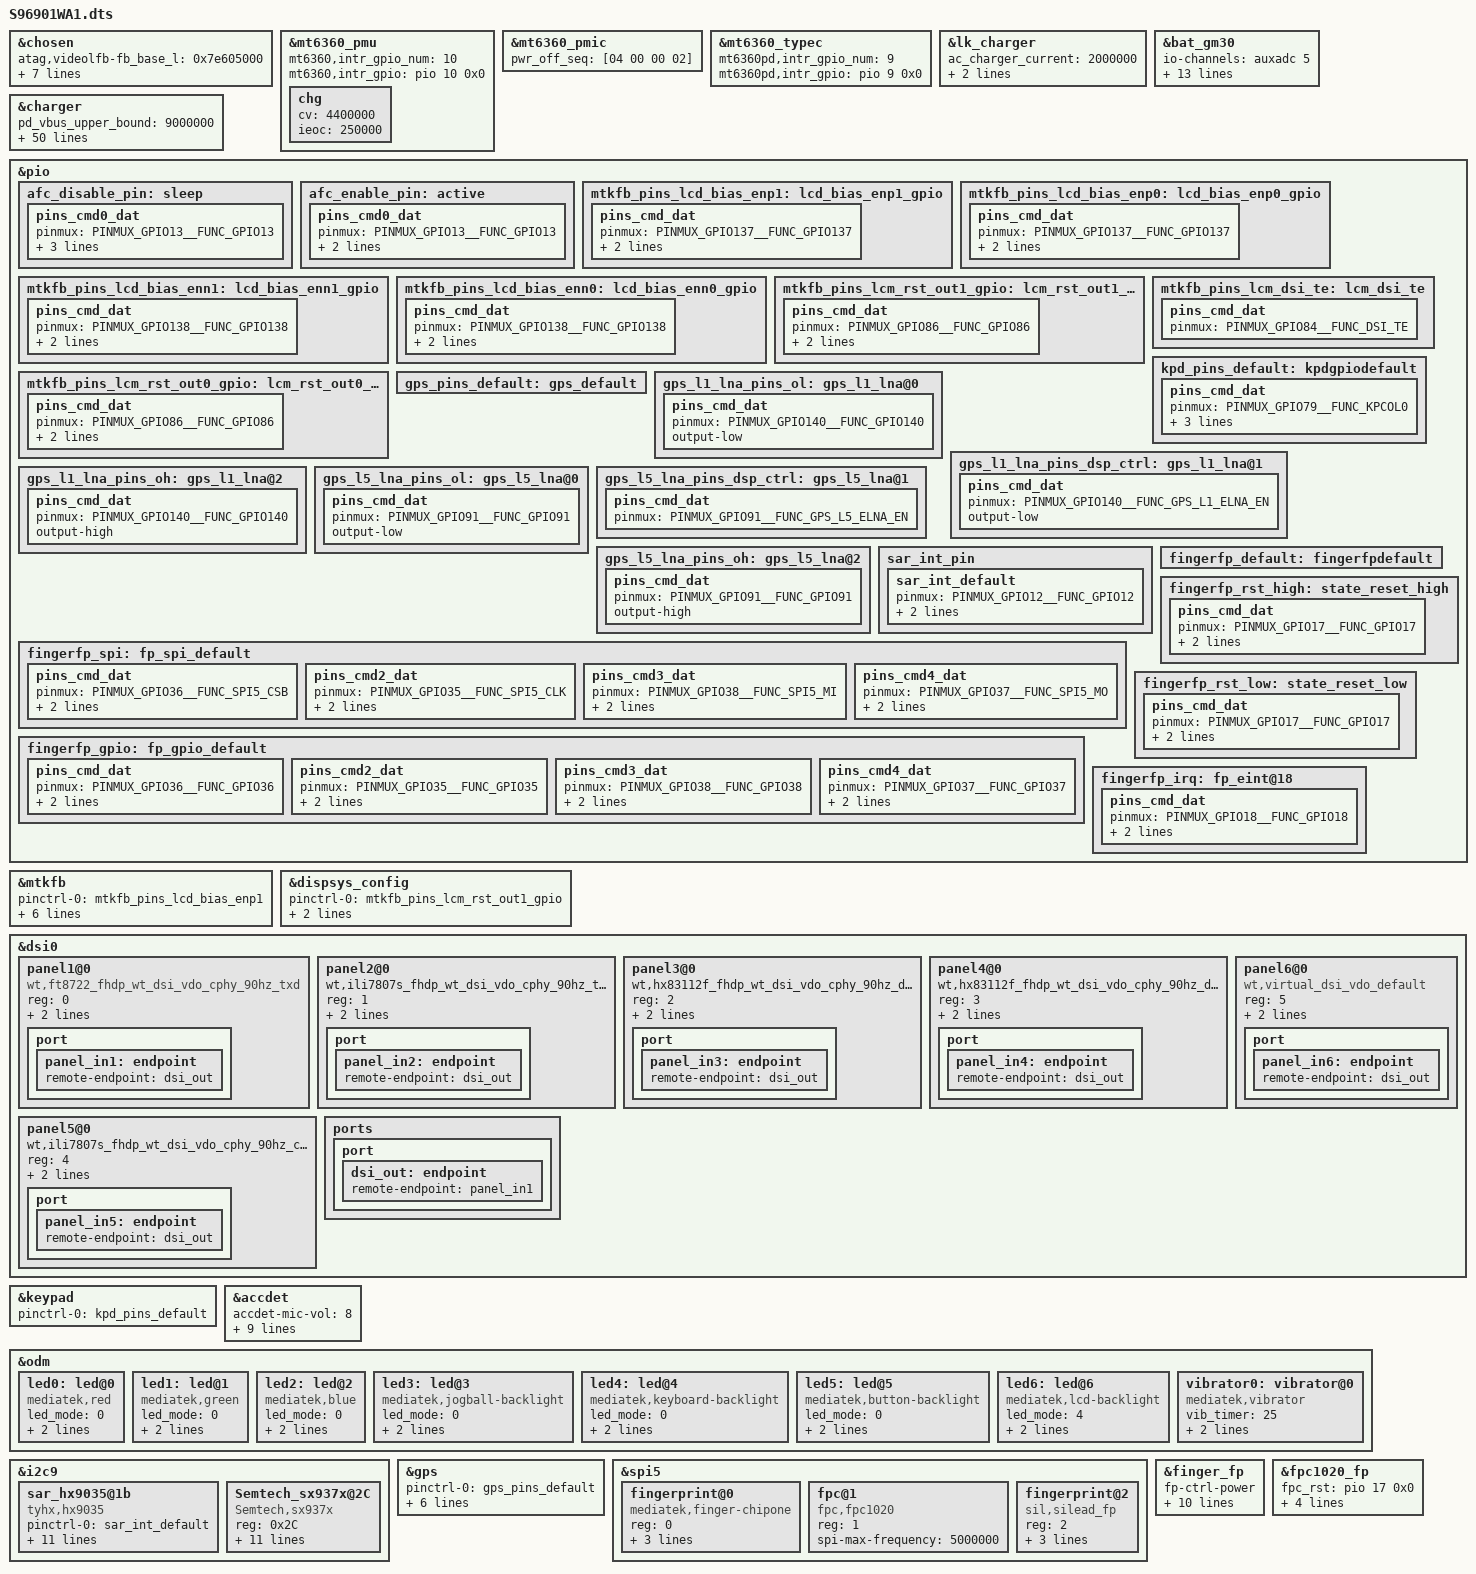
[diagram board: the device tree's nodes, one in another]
// SPDX-License-Identifier: GPL-2.0
/*
 * Copyright (c) 2019 MediaTek Inc.
 *
 */
/dts-v1/;
/plugin/;
#include <dt-bindings/interrupt-controller/irq.h>
#include <dt-bindings/interrupt-controller/arm-gic.h>
#ifndef CONFIG_FPGA_EARLY_PORTING
#include <dt-bindings/pinctrl/mt6833-pinfunc.h>
#endif

/* chosen */
&chosen {
	atag,videolfb-fb_base_l = <0x7e605000>;
	atag,videolfb-fb_base_h = <0x0>;
	atag,videolfb-islcmfound = <1>;
	atag,videolfb-islcm_inited = <0>;
	atag,videolfb-fps= <6000>;
	atag,videolfb-vramSize= <0x1be0000>;
	atag,videolfb-lcmname=
		"nt35595_fhd_dsi_cmd_truly_nt50358_drv";
};

&mt6360_pmu {
	mt6360,intr_gpio_num = <10>; /* direct defined GPIO num */
	mt6360,intr_gpio = <&pio 10 0x0>;
};

&mt6360_pmic {
	pwr_off_seq = [04 00 00 02];
};

&mt6360_typec {
	mt6360pd,intr_gpio_num = <9>; /* direct defined GPIO num */
	mt6360pd,intr_gpio = <&pio 9 0x0>;
};

/* zhaosidong.wt add for bringup*/
&lk_charger {
	ac_charger_current = <2000000>;
	ac_charger_input_current = <2000000>;
	ta_ac_charger_current = <2000000>;
};

&bat_gm30 {
	io-channels = <&auxadc 5>;
	io-channel-names = "batteryID-channel";
#include "mediatek/bat_setting/battery_W2_SCUD_4V4_5000mAh.dtsi"
#include "mediatek/bat_setting/battery_W2_BYD_4V4_5000mAh.dtsi"
	wt,batt-cycle-ranges = <
		0   299  4400000
		300 399  4380000
		400 699  4360000
		700 999  4340000
		1000 999999 4290000>;
	ACTIVE_TABLE = <(5)>;
	g_FG_PSEUDO100_cv4400 = <
		100 100 100 100
		100 100 100 100
		100 100 100 100
		100 100 100 100
		100 100 100 100
		100 100 100 100
		100 100 100 100
		100 100 100 100
		100 100 100 100
		100 100 100 100>;
	g_FG_PSEUDO100_cv4380 = <
		98 98 100 100
		99 98 100 100
		99 98 100 100
		99 98 100 100
		99 99 100 100
		100 100 100 100
		100 100 100 100
		100 100 100 100
		100 100 100 100
		100 100 100 100>;
	g_FG_PSEUDO100_cv4360 = <
		97 96 100 100
		97 96 100 100
		97 96 100 100
		98 96 100 100
		98 97 100 100
		100 100 100 100
		100 100 100 100
		100 100 100 100
		100 100 100 100
		100 100 100 100>;
	g_FG_PSEUDO100_cv4340 = <
		96 95 100 100
		96 95 100 100
		96 94 100 100
		97 95 100 100
		97 96 100 100
		100 100 100 100
		100 100 100 100
		100 100 100 100
		100 100 100 100
		100 100 100 100>;
	g_FG_PSEUDO100_cv4290 = <
		92 90 100 100
		92 90 100 100
		92 90 100 100
		93 91 100 100
		94 92 100 100
		100 100 100 100
		100 100 100 100
		100 100 100 100
		100 100 100 100
		100 100 100 100>;
};

&mt6360_pmu {
	chg {
		cv = <4400000>;
		ieoc = <250000>;
	};
};

/* zhaosidong.wt, 2020/12/16, charger parameters configuration */
&charger {
	pd_vbus_upper_bound = <9000000>;
	enable_sw_jeita;
	/* sw jeita */
	jeita_temp_above_t4_cv = <4100000>;
	jeita_temp_t3_to_t4_cv = <4100000>;
	jeita_temp_t2_to_t3_cv = <4400000>;
	jeita_temp_t1_to_t2_cv = <4400000>;
	jeita_temp_t0_to_t1_cv = <4400000>;
	jeita_temp_below_t0_cv = <4400000>;
	jeita_temp_above_t4_cc = <0>;
	jeita_temp_t3_to_t4_cc = <1400000>;
	jeita_temp_t2_to_t3_cc = <2000000>;
	jeita_temp_t1_to_t2_cc = <1200000>;
	jeita_temp_t0_to_t1_cc = <400000>;
	jeita_temp_below_t0_cc = <0>;
	temp_t4_thres = <55>;
	temp_t4_thres_minus_x_degree = <54>;
	temp_t3_thres = <45>;
	temp_t3_thres_minus_x_degree = <44>;
	temp_t2_thres = <10>;
	temp_t2_thres_plus_x_degree = <11>;
	temp_t1_thres = <5>;
	temp_t1_thres_plus_x_degree = <6>;
	temp_t0_thres = <1>;
	temp_t0_thres_plus_x_degree = <1>;
	temp_neg_10_thres = <0>;

	/* battery temperature protection */
	enable_min_charge_temp;
	min_charge_temp = <0>;
	min_charge_temp_plus_x_degree = <0>;
	max_charge_temp = <60>;
	max_charge_temp_minus_x_degree = <60>;

	battery_cv = <4400000>;
	max_charger_voltage = <10000000>;
	ac_charger_current = <2000000>;
	ac_charger_input_current = <2000000>;
	ta_ac_charger_current = <3000000>;
	enable_pe_2;
	enable_afc;  /*enable for afc fast charge */
	afc_switch_gpio_num = <139>;
	afc_switch_gpio = <&pio 139 0x0>;
	afc_data_gpio_num = <13>;
	afc_data_gpio = <&pio 13 0x0>;
	afc_start_battery_soc = <0>;
	afc_stop_battery_soc = <85>;
	afc_pre_input_curret = <500000>;
	afc_charger_input_current = <1670000>;
	afc_charger_current = <3000000>;
	afc_ichg_level_threshold = <1000000>;
	afc_min_charger_voltage = <4200000>;
	afc_max_charger_voltage = <9000000>;
	pinctrl-names = "active", "sleep";
	pinctrl-0 = <&afc_enable_pin>;
	pinctrl-1 = <&afc_disable_pin>;
	status = "okay";
};

&pio {
	afc_disable_pin: sleep {
		pins_cmd0_dat {
			pinmux = <PINMUX_GPIO13__FUNC_GPIO13>;
			drive-strength = <4>;
			input-enable;
			bias-disable;
		};
	};

	afc_enable_pin: active {
		pins_cmd0_dat {
			pinmux = <PINMUX_GPIO13__FUNC_GPIO13>;
			drive-strength = <4>;
			bias-disable;
		};
	};
};

#ifndef CONFIG_FPGA_EARLY_PORTING
&pio {
	mtkfb_pins_lcd_bias_enp1: lcd_bias_enp1_gpio {
		pins_cmd_dat {
			pinmux = <PINMUX_GPIO137__FUNC_GPIO137>;
			slew-rate = <1>;
			output-high;
		};
	};

	mtkfb_pins_lcd_bias_enp0: lcd_bias_enp0_gpio {
		pins_cmd_dat {
			pinmux = <PINMUX_GPIO137__FUNC_GPIO137>;
			slew-rate = <1>;
			output-low;
		};
	};

	mtkfb_pins_lcd_bias_enn1: lcd_bias_enn1_gpio {
		pins_cmd_dat {
			pinmux = <PINMUX_GPIO138__FUNC_GPIO138>;
			slew-rate = <1>;
			output-high;
		};
	};

	mtkfb_pins_lcd_bias_enn0: lcd_bias_enn0_gpio {
		pins_cmd_dat {
			pinmux = <PINMUX_GPIO138__FUNC_GPIO138>;
			slew-rate = <1>;
			output-low;
		};
	};

	mtkfb_pins_lcm_rst_out1_gpio: lcm_rst_out1_gpio {
		pins_cmd_dat {
			pinmux = <PINMUX_GPIO86__FUNC_GPIO86>;
			slew-rate = <1>;
			output-high;
		};
	};

	mtkfb_pins_lcm_rst_out0_gpio: lcm_rst_out0_gpio {
		pins_cmd_dat {
			pinmux = <PINMUX_GPIO86__FUNC_GPIO86>;
			slew-rate = <1>;
			output-low;
		};
	};
	mtkfb_pins_lcm_dsi_te: lcm_dsi_te {
		pins_cmd_dat {
			pinmux = <PINMUX_GPIO84__FUNC_DSI_TE>;
		};
	};
};

&mtkfb {
	pinctrl-names = "lcd_bias_enp1_gpio", "lcd_bias_enp0_gpio",
		"lcd_bias_enn1_gpio", "lcd_bias_enn0_gpio",
		"lcm_rst_out1_gpio", "lcm_rst_out0_gpio",
		"mode_te_te";
	pinctrl-0 = <&mtkfb_pins_lcd_bias_enp1>;
	pinctrl-1 = <&mtkfb_pins_lcd_bias_enp0>;
	pinctrl-2 = <&mtkfb_pins_lcd_bias_enn1>;
	pinctrl-3 = <&mtkfb_pins_lcd_bias_enn0>;
	pinctrl-4 = <&mtkfb_pins_lcm_rst_out1_gpio>;
	pinctrl-5 = <&mtkfb_pins_lcm_rst_out0_gpio>;
	pinctrl-6 = <&mtkfb_pins_lcm_dsi_te>;
	status = "okay";
};
&dispsys_config {
	pinctrl-names =
		"lcm_rst_out1_gpio", "lcm_rst_out0_gpio",
		"mode_te_te";
	pinctrl-0 = <&mtkfb_pins_lcm_rst_out1_gpio>;
	pinctrl-1 = <&mtkfb_pins_lcm_rst_out0_gpio>;
	pinctrl-2 = <&mtkfb_pins_lcm_dsi_te>;
	status = "okay";
};

&dsi0 {
	status = "okay";
	#address-cells = <1>;
	#size-cells = <0>;
	panel1@0 {
		compatible = "wt,ft8722_fhdp_wt_dsi_vdo_cphy_90hz_txd";
		reg = <0>;
		//pm-enable-gpios = <&pio 136 0>;
		reset-gpios = <&pio 86 0>;
		bias-gpios = <&pio 137 0>,
			<&pio 138 0>;
		pinctrl-names = "default";
		port {
			panel_in1: endpoint {
				remote-endpoint = <&dsi_out>;
			};
		};
	};

	panel2@0 {
		compatible = "wt,ili7807s_fhdp_wt_dsi_vdo_cphy_90hz_tianma";
		reg = <1>;
		//pm-enable-gpios = <&pio 136 0>;
		reset-gpios = <&pio 86 0>;
		bias-gpios = <&pio 137 0>,
			<&pio 138 0>;
		pinctrl-names = "default";
		port {
			panel_in2: endpoint {
				remote-endpoint = <&dsi_out>;
			};
		};
	};

	panel3@0 {
		compatible = "wt,hx83112f_fhdp_wt_dsi_vdo_cphy_90hz_dsbj";
		reg = <2>;
		//pm-enable-gpios = <&pio 136 0>;
		reset-gpios = <&pio 86 0>;
		bias-gpios = <&pio 137 0>,
			<&pio 138 0>;
		pinctrl-names = "default";
		port {
			panel_in3: endpoint {
				remote-endpoint = <&dsi_out>;
			};
		};
	};

	panel4@0 {
		compatible = "wt,hx83112f_fhdp_wt_dsi_vdo_cphy_90hz_djn";
		reg = <3>;
		//pm-enable-gpios = <&pio 136 0>;
		reset-gpios = <&pio 86 0>;
		bias-gpios = <&pio 137 0>,
			<&pio 138 0>;
		pinctrl-names = "default";
		port {
			panel_in4: endpoint {
				remote-endpoint = <&dsi_out>;
			};
		};
	};
	
	panel5@0 {
		compatible = "wt,ili7807s_fhdp_wt_dsi_vdo_cphy_90hz_chuangwei";
		reg = <4>;
		//pm-enable-gpios = <&pio 136 0>;
		reset-gpios = <&pio 86 0>;
		bias-gpios = <&pio 137 0>,
			<&pio 138 0>;
		pinctrl-names = "default";
		port {
			panel_in5: endpoint {
				remote-endpoint = <&dsi_out>;
			};
		};
	};

	panel6@0 {
		compatible = "wt,virtual_dsi_vdo_default";
		reg = <5>;
		//pm-enable-gpios = <&pio 136 0>;
		reset-gpios = <&pio 86 0>;
		bias-gpios = <&pio 137 0>,
			<&pio 138 0>;
		pinctrl-names = "default";
		port {
			panel_in6: endpoint {
				remote-endpoint = <&dsi_out>;
			};
		};
	};

	ports {
		port {
			dsi_out: endpoint {
				remote-endpoint = <&panel_in1>;
			};
		};
	};
};
#endif

&keypad {
	pinctrl-names = "default";
	pinctrl-0 = <&kpd_pins_default>;
};

&pio {
	kpd_pins_default: kpdgpiodefault {
		pins_cmd_dat {
			pinmux = <PINMUX_GPIO79__FUNC_KPCOL0>;
			bias-pull-up = <MTK_PUPD_SET_R1R0_10>;
			output-low;
			input-schmitt-enable;
		};
	};
};


#include "mediatek/cust_mt6833_touch_ft8722_1080x2400.dtsi"

/* accdet start */
&accdet {
	/* accdet micbias voltage: 0x09:2.85v 0x08:2.8v 0x07,
	 * 2.7v;0x05,2.5v;0x02,1.9v
	 */
	accdet-mic-vol = <8>;
	/* accdet pwm_width, pwm_thresh, fall_delay, rise_delay
	 * debounce0, debounce1, debounce3, debounce4
	 * eint pwm_width, eint pwm_thresh
	 * eint deb(debounce0, debounce1, debounce2, debounce3), inv_debounce
	 */
	headset-mode-setting = <0x500 0x500 1 0x1f0
				0x1000 0x1000 0xc80 0x44
				0x4 0x1
				0x5 0x3 0x3 0x5 0xe>;
	accdet-plugout-debounce = <1>;
	/*1:ACC mode, 2:low cost without in bias, 6:low cost with in bias*/
	accdet-mic-mode = <2>;
	/*min_3pole--max_3pole--min_4pole--max_4pole--vol_bias*/
	headset-vol-threshold = <0 350 351 1580 1700>;
	/*0--MD_MAX--UP_MAX--DW_MAX*/
	headset-three-key-threshold = <0 80 220 400>;
	headset-three-key-threshold-CDD = <0 121 192 600>;
	/*0--MD_MAX--VOICE_MAX--UP_MAX--DW_MAX*/
	headset-four-key-threshold = <0 58 121 192 400>;

	/* select VTH to 2v and 500k, use internal resitance */
	eint_use_ext_res = <0>;
	status = "okay";
};
/* accdet end */

&odm {
	led0:led@0 {
		compatible = "mediatek,red";
		led_mode = <0>;
		data = <1>;
		pwm_config = <0 0 0 0 0>;
	};
	led1:led@1 {
		compatible = "mediatek,green";
		led_mode = <0>;
		data = <1>;
		pwm_config = <0 0 0 0 0>;
	};
	led2:led@2 {
		compatible = "mediatek,blue";
		led_mode = <0>;
		data = <1>;
		pwm_config = <0 0 0 0 0>;
	};
	led3:led@3 {
		compatible = "mediatek,jogball-backlight";
		led_mode = <0>;
		data = <1>;
		pwm_config = <0 0 0 0 0>;
	};
	led4:led@4 {
		compatible = "mediatek,keyboard-backlight";
		led_mode = <0>;
		data = <1>;
		pwm_config = <0 0 0 0 0>;
	};
	led5:led@5 {
		compatible = "mediatek,button-backlight";
		led_mode = <0>;
		data = <1>;
		pwm_config = <0 0 0 0 0>;
	};
	led6:led@6 {
		compatible = "mediatek,lcd-backlight";
		led_mode = <4>;
		data = <1>;
		pwm_config = <0 1 0 0 0>;
	};
	vibrator0:vibrator@0 {
		compatible = "mediatek,vibrator";
		vib_timer = <25>;
		vib_limit = <9>;
		vib_vol= <13>;
	};
};
/* GPS GPIO standardization start */
&pio {
	gps_pins_default: gps_default {
	};

	gps_l1_lna_pins_ol: gps_l1_lna@0 {
		pins_cmd_dat {
			pinmux = <PINMUX_GPIO140__FUNC_GPIO140>;
			output-low;
		};
	};
	gps_l1_lna_pins_dsp_ctrl: gps_l1_lna@1 {
		pins_cmd_dat {
			pinmux = <PINMUX_GPIO140__FUNC_GPS_L1_ELNA_EN>;
			output-low;
		};
	};
	gps_l1_lna_pins_oh: gps_l1_lna@2 {
		pins_cmd_dat {
			pinmux = <PINMUX_GPIO140__FUNC_GPIO140>;
			output-high;
		};
	};

	gps_l5_lna_pins_ol: gps_l5_lna@0 {
		pins_cmd_dat {
			pinmux = <PINMUX_GPIO91__FUNC_GPIO91>;
			output-low;
		};
	};
	gps_l5_lna_pins_dsp_ctrl: gps_l5_lna@1 {
		pins_cmd_dat {
			pinmux = <PINMUX_GPIO91__FUNC_GPS_L5_ELNA_EN>;
		};
	};
	gps_l5_lna_pins_oh: gps_l5_lna@2 {
		pins_cmd_dat {
			pinmux = <PINMUX_GPIO91__FUNC_GPIO91>;
			output-high;
		};
	};
};

&i2c9 {
    status = "okay";
    sar_hx9035@1b {
        compatible = "tyhx,hx9035";
        pinctrl-names = "sar_int_default";
        pinctrl-0 = <&sar_int_default>;
        i2c_num = <1>;
        reg = <0x1b>;
        interrupt-parent = <&pio>;
        interrupts = <12 IRQ_TYPE_EDGE_FALLING 12 0>;
        tyhx,irq-gpio = <&pio 12 0x0>;
        tyhx,irq-flags = <2>; /* 1:rising, 2:falling;*/
        tyhx,button-flag = <0xFF>;
        tyhx,channel-flag = <0xFF>;
        grip-sensor = <0>;
        grip-sensor-sub = <1>;
        grip-sensor-wifi = <2>;
        status = "okay";
    };
    Semtech_sx937x@2C {
        status = "okay";
        compatible = "Semtech,sx937x";
        reg = <0x2C>;
        pinctrl-names = "sar_int_default";
        pinctrl-0 = <&sar_int_default>;
        interrupt-parent = <&pio>;
        interrupts = <12 IRQ_TYPE_EDGE_FALLING 12 0>;
        //interrupt-names = "sx937x_irq";
        Semtech,nirq-gpio = <&pio 12 0x0>;
        Semtech,button-flag = <0x7>;
        /*use PH4/5/6 as the reference sensor
        set it to 0xff if the ref-phases-x is not used*/
        Semtech,ref-phases-a = <3>;
        Semtech,ref-phases-b = <4>;
        Semtech,ref-phases-c = <5>;
        Semtech,reg-num = <59>;
        Semtech,reg-init = <
            0x8024 0x7F00
            0x4004 0x70
            0x4008 0x8
            0x8020 0x32
            0x8028 0x846
            0x8034 0x846
            0x8040 0x446
            0x804C 0xD46
            0x8058 0x846
            0x8064 0x446
            0x8070 0x846
            0x807C 0x88E
            0x8030 0xFFF9FD
            0x803C 0xF7F9FF
            0x8048 0xFFD9FF
            0x8054 0xFFF9EF
            0x8060 0xFEF9FF
            0x806C 0xBFF9FF
            0x8078 0xFFFFFF
            0x8084 0xFFFFFF
            0x8098 0x60
            0x80B8 0x39
            0x80D8 0x1A
            0x80F8 0xFF
            0x8118 0xFF
            0x8138 0xFF
            0x8158 0xFF
            0x80A0 0x80800001
            0x80C0 0x20200002
            0x80E0 0x10100003
            0x8188 0x8000013
            0x818C 0x8000014
            0x8190 0x8000015
            0x8090 0x54AC5000
            0x80B0 0x54AC5000
            0x80D0 0x54A75000
            0x80F0 0x5300
            0x8110 0x5300
            0x8130 0x5300
            0x8150 0x5300
            0x8170 0x2AD66000
            0x8088 0x300005
            0x80A8 0x300005
            0x80C8 0x300005
            0x80E8 0x6300000
            0x8108 0x6300000
            0x8128 0x6300000
            0x8148 0x6300000
            0x8168 0x300000
            0x808C 0x60200078
            0x80AC 0x60200078
            0x80CC 0x60200078
            0x80EC 0x60200030
            0x810C 0x60200030
            0x812C 0x60200030
            0x814C 0x60200030
            0x816C 0x60200030
            0x8274 0x2E040000
            /*0x8024 0x3F3F*/
            0x4280 0xE
>;
	};

};

&pio {
    sar_int_pin {
        sar_int_default: sar_int_default {
            pinmux = <PINMUX_GPIO12__FUNC_GPIO12>;
            slew-rate = <2>;
            bias-pull-up;
        };
    };
};

&gps {
	pinctrl-names = "default",
		"gps_l1_lna_disable",
		"gps_l1_lna_dsp_ctrl",
		"gps_l1_lna_enable",
		"gps_l5_lna_disable",
		"gps_l5_lna_dsp_ctrl",
		"gps_l5_lna_enable";
	pinctrl-0 = <&gps_pins_default>;
	pinctrl-1 = <&gps_l1_lna_pins_ol>;
	pinctrl-2 = <&gps_l1_lna_pins_dsp_ctrl>;
	pinctrl-3 = <&gps_l1_lna_pins_oh>;
	pinctrl-4 = <&gps_l5_lna_pins_ol>;
	pinctrl-5 = <&gps_l5_lna_pins_dsp_ctrl>;
	pinctrl-6 = <&gps_l5_lna_pins_oh>;
	status = "okay";
};
/* GPS GPIO standardization end */

/* FINGERPRINT start */
&spi5 {
        #address-cells = <1>;
        #size-cells = <0>;
	fingerprint@0 {
               compatible = "mediatek,finger-chipone";
               reg = <0>;
               spi-max-frequency = <8000000>;
               netlink-event = <30>;
               fp_vdd-supply = <&mt_pmic_vfp_ldo_reg>;
               status = "okay";
        };
        fpc@1 {
                reg = <1>;
               	compatible = "fpc,fpc1020";
                spi-max-frequency = <5000000>;
                status = "okay";
    	};
       	fingerprint@2 {
	        compatible = "sil,silead_fp";
	        reg = <2>;
	        spi-max-frequency = <8000000>;
	        netlink-event = <30>;
                fp_vdd-supply = <&mt_pmic_vfp_ldo_reg>;
	        status = "okay";
	};
};

&finger_fp {
       fp-ctrl-power;
       fp_vdd-supply = <&mt_pmic_vfp_ldo_reg>;
       int-gpios = <&pio 18 0>;
       interrupt-parent = <&pio>;
       interrupts = <18 IRQ_TYPE_EDGE_RISING 18 0>;
       pinctrl-names = "default", "rst-low", "rst-high" ,
                       "irq-init", "spi-default","gpio-default";
       pinctrl-0 = <&fingerfp_default>;
       pinctrl-1 = <&fingerfp_rst_low>;
       pinctrl-2 = <&fingerfp_rst_high>;
       pinctrl-3 = <&fingerfp_irq>;
       pinctrl-4 = <&fingerfp_spi>;
       pinctrl-5 = <&fingerfp_gpio>;
       status = "okay";
};

&pio {
       fingerfp_spi: fp_spi_default {
               pins_cmd_dat {
                       pinmux = <PINMUX_GPIO36__FUNC_SPI5_CSB>;
                       slew-rate = <1>;
                       bias-pull-up;
               };

               pins_cmd2_dat {
                       pinmux = <PINMUX_GPIO35__FUNC_SPI5_CLK>;
                       slew-rate = <1>;
                       bias-pull-down;
               };

               pins_cmd3_dat {
                       pinmux = <PINMUX_GPIO38__FUNC_SPI5_MI>;
                       slew-rate = <0>;
                       bias-pull-down;
               };

               pins_cmd4_dat {
                       pinmux = <PINMUX_GPIO37__FUNC_SPI5_MO>;
                       slew-rate = <1>;
                       bias-pull-down;
               };
       };
       fingerfp_gpio: fp_gpio_default {
               pins_cmd_dat {
                       pinmux = <PINMUX_GPIO36__FUNC_GPIO36>;
                       slew-rate = <1>;
                       bias-pull-up;
               };

               pins_cmd2_dat {
                       pinmux = <PINMUX_GPIO35__FUNC_GPIO35>;
                       slew-rate = <1>;
                       bias-pull-down;
               };

               pins_cmd3_dat {
                       pinmux = <PINMUX_GPIO38__FUNC_GPIO38>;
                       slew-rate = <0>;
                       bias-pull-down;
               };

               pins_cmd4_dat {
                       pinmux = <PINMUX_GPIO37__FUNC_GPIO37>;
                       slew-rate = <1>;
                       bias-pull-down;
               };
       };

       fingerfp_default: fingerfpdefault {
       };

       fingerfp_rst_high: state_reset_high {
               pins_cmd_dat {
                       pinmux = <PINMUX_GPIO17__FUNC_GPIO17>;
                       slew-rate = <1>;
                       output-high;
               };
       };

       fingerfp_rst_low: state_reset_low {
               pins_cmd_dat {
                       pinmux = <PINMUX_GPIO17__FUNC_GPIO17>;
                       slew-rate = <1>;
                       output-low;
               };
       };

       fingerfp_irq: fp_eint@18 {
               pins_cmd_dat {
                       pinmux = <PINMUX_GPIO18__FUNC_GPIO18>;
                       slew-rate = <0>;
                       bias-disable;
               };
       };

};

&fpc1020_fp {
	fpc_rst = <&pio 17 0x0>;
	fpc_irq = <&pio 18 0x0>;
	//fpc_vdd = <&pio 10 0x0>;
	vfp-supply = <&mt_pmic_vfp_ldo_reg>; // use regulator power
	interrupt-parent = <&pio>;
	interrupts = <18 IRQ_TYPE_EDGE_RISING 18 0>;
	status = "okay";
};
/* FINGERPRINT end */

#include "mediatek/cust_mt6833_camera.dtsi"
#include "mediatek/S96901WA1/cust.dtsi"
#include "mediatek/fs1815n.dtsi"

/*End of this file, DO NOT ADD ANYTHING HERE*/
